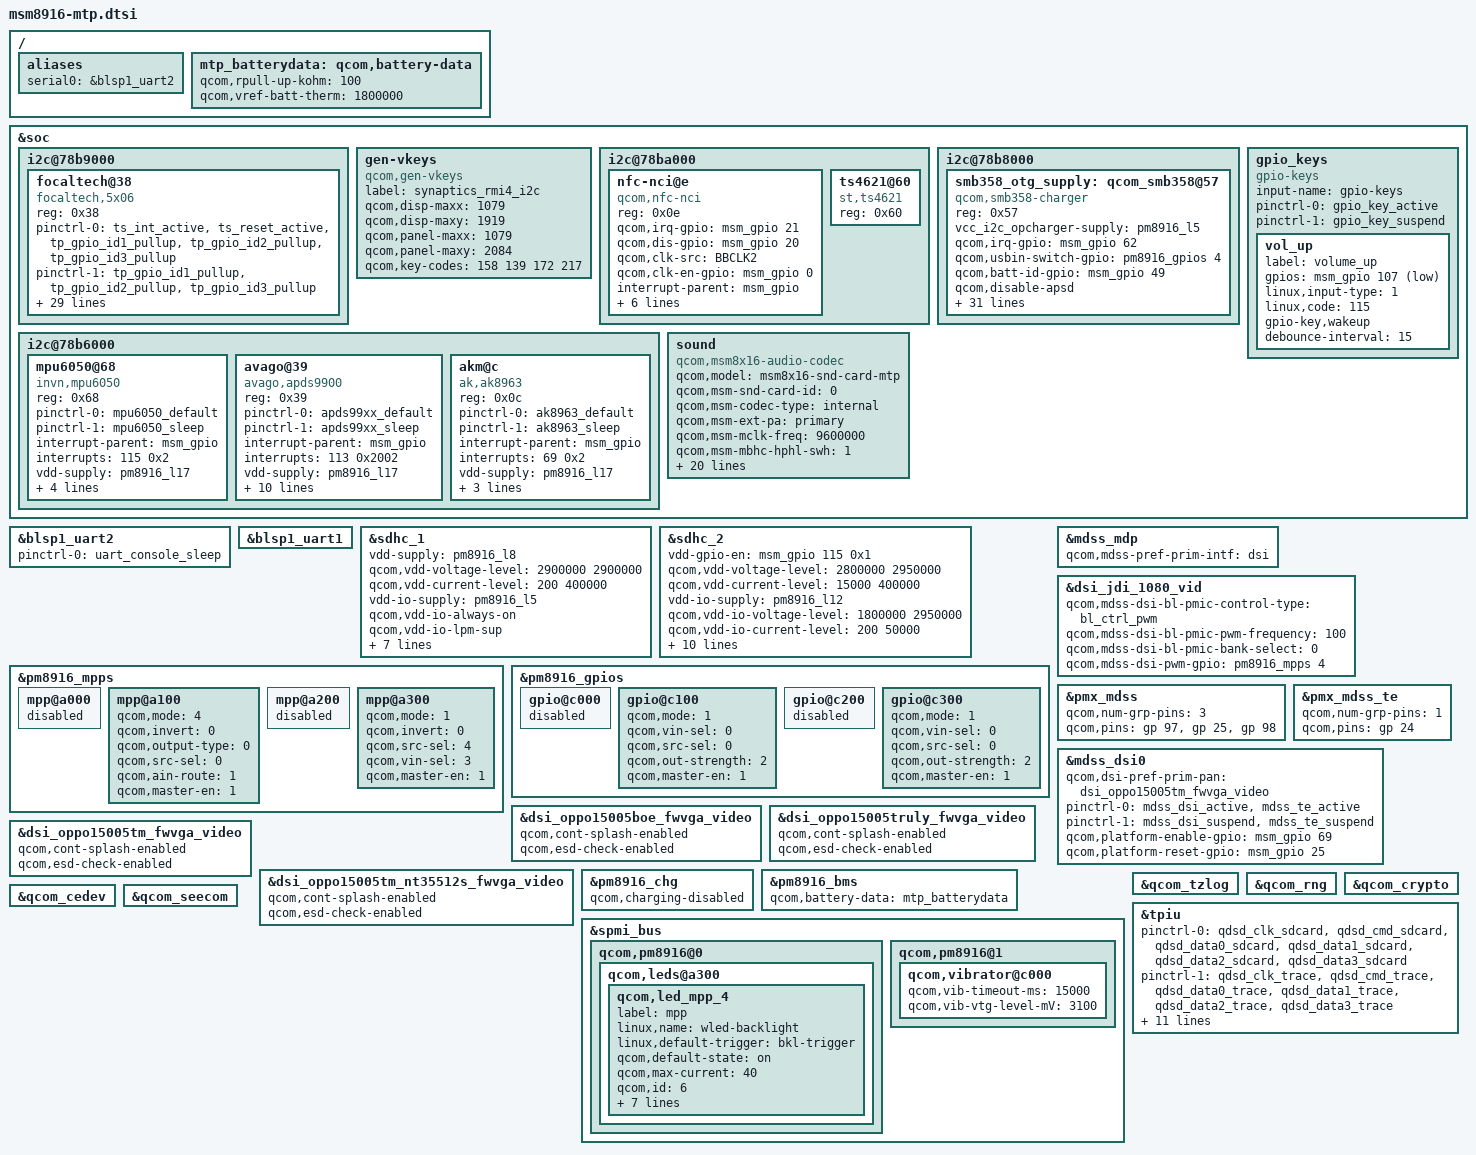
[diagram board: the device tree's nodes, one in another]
/* Copyright (c) 2014, The Linux Foundation. All rights reserved.
 *
 * This program is free software; you can redistribute it and/or modify
 * it under the terms of the GNU General Public License version 2 and
 * only version 2 as published by the Free Software Foundation.
 *
 * This program is distributed in the hope that it will be useful,
 * but WITHOUT ANY WARRANTY; without even the implied warranty of
 * MERCHANTABILITY or FITNESS FOR A PARTICULAR PURPOSE.  See the
 * GNU General Public License for more details.
 */

#include "msm8916.dtsi"
#include "msm8916-pinctrl.dtsi"
#include "msm8916-camera-sensor-mtp.dtsi"
/*YongPeng.Yi@PhoneSW.Multimedia, 2015/01/08 Add for 15005 LCD*/
#include "dsi-panel-oppo15005tm-fwvga-video.dtsi"
#include "dsi-panel-oppo15005boe-fwvga-video.dtsi"
#include "dsi-panel-oppo15005tm-nt35512s-fwvga-video.dtsi"
/*wuyu@EXP.BaseDrv.LCM, 2015/02/09 add for 15065 LCD*/
#include "dsi-panel-oppo15005truly-fwvga-video.dtsi"

#include "msm8916-generic-sensors.dtsi"
/ {
	aliases {
		serial0 = &blsp1_uart2;
	};
};

&soc {
	i2c@78b9000 { /* BLSP1 QUP5 */
		focaltech@38 {
		compatible = "focaltech,5x06";
		reg = <0x38>;
		
		
		pinctrl-names = "default","tp_id_pull_up","tp_id_pull_down";
		pinctrl-0 = <&ts_int_active &ts_reset_active &tp_gpio_id1_pullup &tp_gpio_id2_pullup &tp_gpio_id3_pullup>;
		pinctrl-1 = <&tp_gpio_id1_pullup   &tp_gpio_id2_pullup   &tp_gpio_id3_pullup>;
		pinctrl-2 = <&tp_gpio_id1_pulldown &tp_gpio_id2_pulldown &tp_gpio_id3_pulldown>;
		
		interrupt-parent = <&msm_gpio>;
		interrupts = <13 0x8>;
		vdd-supply = <&pm8916_l17>;
		vcc_i2c-supply = <&pm8916_l6>;
		focaltech,name = "ft5x06";
		focaltech,family-id = <0x54>;
		focaltech,reset-gpio = <&msm_gpio 21 0x00>;
		focaltech,irq-gpio =<&msm_gpio 13 0x00>;
		focaltech,id1-gpio = <&msm_gpio 109 0x00>;
		focaltech,id2-gpio = <&msm_gpio 114 0x00>;
		focaltech,id3-gpio = <&msm_gpio 121 0x00>;
		focaltech,display-coords = <0 0 480 854>;
		focaltech,panel-coords = <0 0 480 854>;
		focaltech,button-map= <85 100 900>;
		focaltech,no-force-update;
		focaltech,i2c-pull-up;
		focaltech,group-id = <1>;
		focaltech,hard-reset-delay-ms = <20>;
		focaltech,soft-reset-delay-ms = <150>;
		focaltech,num-max-touches = <10>;
		focaltech,fw-name = "FT_Upgrade_App.i";
		focaltech,fw-delay-aa-ms = <50>;
		focaltech,fw-delay-55-ms = <30>;
		focaltech,fw-upgrade-id1 = <0x79>;
		focaltech,fw-upgrade-id2 = <0x03>;
		focaltech,fw-delay-readid-ms = <10>;
		focaltech,fw-delay-era-flsh-ms = <2000>;
		};
	};

	gen-vkeys {
		compatible = "qcom,gen-vkeys";
		label = "synaptics_rmi4_i2c";
		qcom,disp-maxx = <1079>;
		qcom,disp-maxy = <1919>;
		qcom,panel-maxx = <1079>;
		qcom,panel-maxy = <2084>;
		qcom,key-codes = <158 139 172 217>;
	};

	i2c@78ba000 { /* BLSP1 QUP6 */
		nfc-nci@e {
			compatible = "qcom,nfc-nci";
			reg = <0x0e>;
			qcom,irq-gpio = <&msm_gpio 21 0x00>;
			qcom,dis-gpio = <&msm_gpio 20 0x00>;
			qcom,clk-src = "BBCLK2";
			qcom,clk-en-gpio = <&msm_gpio 0 0x00>;
			interrupt-parent = <&msm_gpio>;
			interrupts = <21 0>;
			interrupt-names = "nfc_irq";
			pinctrl-names = "nfc_active","nfc_suspend";
			pinctrl-0 = <&nfc_int_active &nfc_disable_active>;
			pinctrl-1 = <&nfc_int_suspend &nfc_disable_suspend>;
			qcom,clk-gpio = <&pm8916_gpios 2 0>;
			clocks = <&clock_rpm clk_bb_clk2_pin>;
			clock-names = "ref_clk";
		};
                /* OPPO 2014-10-24 John.Xu@Audio.Driver Add begin for ts4621 */
                //#ifdef VENDOR_EDIT
    	        ts4621@60 {
    	                  status = "okay";
                          compatible = "st,ts4621";
                          reg = <0x60>;
                };
               //#endif
               /* OPPO 2014-10-24 John.Xu@Audio.Driver Add end */
	};

	i2c@78b6000 { /* BLSP1 QUP2 */
		mpu6050@68 { /* Gyroscope and accelerometer sensor combo */
			compatible = "invn,mpu6050";
			reg = <0x68>;
			pinctrl-names = "mpu_default","mpu_sleep";
			pinctrl-0 = <&mpu6050_default>;
			pinctrl-1 = <&mpu6050_sleep>;
			interrupt-parent = <&msm_gpio>;
			interrupts = <115 0x2>;
			vdd-supply = <&pm8916_l17>;
			vlogic-supply = <&pm8916_l16>;
			vi2c-supply = <&pm8916_l6>;
			invn,gpio-int = <&msm_gpio 115 0x2>;
			invn,place = "Portrait Down Back Side";
		};

		avago@39 { /* Ambient light and proximity sensor */
			compatible = "avago,apds9900";
			reg = <0x39>;
			pinctrl-names = "default","sleep";
			pinctrl-0 = <&apds99xx_default>;
			pinctrl-1 = <&apds99xx_sleep>;
			interrupt-parent = <&msm_gpio>;
			interrupts = <113 0x2002>;
			vdd-supply = <&pm8916_l17>;
			vio-supply = <&pm8916_l6>;
			avago,irq-gpio = <&msm_gpio 113 0x2002>;
			avago,ps-threshold = <600>;
			avago,ps-hysteresis-threshold = <500>;
			avago,ps-pulse = <8>;
			avago,ps-pgain = <0>;
			avago,als-B = <223>;
			avago,als-C = <70>;
			avago,als-D = <142>;
			avago,ga-value = <48>;
		};

		akm@c {
			compatible = "ak,ak8963";
			reg = <0x0c>;
			pinctrl-names = "ak8963_default", "ak8963_sleep";
			pinctrl-0 = <&ak8963_default>;
			pinctrl-1 = <&ak8963_sleep>;
			interrupt-parent = <&msm_gpio>;
			interrupts = <69 0x2>;
			vdd-supply = <&pm8916_l17>;
			vio-supply = <&pm8916_l6>;
			ak,layout = <0x6>;
			ak,auto-report;
		};
	};
	
	/*Fuchun.Liao@Mobile.BSP.CHG 2014-07-31 add to config BSL1 QUP4 for smb358-charger*/
	i2c@78b8000 {	/* BLSP1 QUP4 */
		smb358_otg_supply:	qcom_smb358@57 {
			compatible = "qcom,smb358-charger";
			reg = <0x57>;
			vcc_i2c_opcharger-supply = <&pm8916_l5>;
			qcom,irq-gpio = <&msm_gpio 62 0x00>;
									
			qcom,usbin-switch-gpio = <&pm8916_gpios 4 0>;
			qcom,batt-id-gpio = <&msm_gpio 49 0x00>;
			
			qcom,disable-apsd;
			qcom,using-pmic-therm;
			//qcom,bms-controlled-charging;
			qcom,charger-inhibit-disabled;
			qcom,bms-psy-name = "bms";
			qcom,chg-vadc = <&pm8916_vadc>;
			qcom,chg-adc_tm = <&pm8916_adc_tm>;
			
			qcom,iterm-ma = <100>;								
			qcom,recharge-mv = <200>;							
			qcom,fast-charger-project-sign= <0>;					
			qcom,fastchg-current-max-ma = <900>;					
			qcom,input-current-max-ma = <1000>; 				
			qcom,float-voltage-mv = <4320>; 					

			qcom,hot_bat_decidegc = <550>;						
			qcom,temp_hot_vfloat_mv = <4100>;						
			qcom,temp_hot_fastchg_current_ma = <512>;				

			qcom,warm_bat_decidegc = <450>; 				
			qcom,temp_warm_vfloat_mv = <4320>;				
			qcom,temp_warm_fastchg_current_ma = <900>; 		

			qcom,pre_normal_bat_decidegc = <200>;					
			qcom,temp_pre_normal_vfloat_mv = <4320>;				
			qcom,temp_pre_normal_fastchg_current_ma = <900>;		

			qcom,pre_cool_bat_decidegc = <100>; 				
			qcom,temp_pre_cool_vfloat_mv = <4200>;				
			qcom,temp_pre_cool_fastchg_current_ma = <512>;		

			qcom,cool_bat_decidegc = <0>;							
			qcom,temp_cool_vfloat_mv = <4000>;					
			qcom,temp_cool_fastchg_current_ma = <250>;		

			qcom,cold_bat_decidegc = <100>; 				
			qcom,bat_present_decidegc = <200>;
			qcom,non_standard_vfloat_mv = <4000>;
			qcom,non_standard_fastchg_current_ma = <512>;
			regulator-name = "smb358_otg_vreg";
		};

	};
	/*Fuchun.Liao add end*/
	
	sound {
		compatible = "qcom,msm8x16-audio-codec";
		qcom,model = "msm8x16-snd-card-mtp";
		qcom,msm-snd-card-id = <0>;
		qcom,msm-codec-type = "internal";
		qcom,msm-ext-pa = "primary";
		qcom,msm-mclk-freq = <9600000>;
		/*xiang.fei@Multimedia, 2014/07/29, Modify for headset*/
		/*qcom,msm-mbhc-hphl-swh = <0>;*/
		qcom,msm-mbhc-hphl-swh = <1>;
		/*xiang.fei@Multimedia, 2014/07/29, Modify end*/
		qcom,msm-mbhc-gnd-swh = <0>;
		qcom,msm-micbias1-ext-cap;
		/*John.Xu@Multimedia, 2015/01/09, Modify for headset*/
		/*qcom,msm-hs-micbias-type = "internal";*/
		qcom,msm-hs-micbias-type = "external";
		/*John.Xu@Multimedia, 2015/01/09, Modify end*/
		qcom,audio-routing =
			"RX_BIAS", "MCLK",
			"SPK_RX_BIAS", "MCLK",
			"INT_LDO_H", "MCLK",
			"MIC BIAS External", "Handset Mic",
			"MIC BIAS Internal2", "Headset Mic",
			"MIC BIAS External", "Secondary Mic",
			"AMIC1", "MIC BIAS External",
			"AMIC2", "MIC BIAS Internal2",
			"AMIC3", "MIC BIAS External";
		pinctrl-names = "cdc_lines_act",
				"cdc_lines_sus",
				"cdc_lines_sec_ext_act",
				"cdc_lines_sec_ext_sus",
				"cross_conn_det_act",
				"cross_conn_det_sus";
		pinctrl-0 = <&cdc_pdm_lines_act>;
		pinctrl-1 = <&cdc_pdm_lines_sus>;
		pinctrl-2 = <&cdc_pdm_lines_act &cdc_ext_pa_act
						&cdc_ext_pa_ws_act>;
		pinctrl-3 = <&cdc_pdm_lines_sus &cdc_ext_pa_sus
						&cdc_ext_pa_ws_sus>;
		pinctrl-4 = <&cross_conn_det_act>;
		pinctrl-5 = <&cross_conn_det_sus>;
		/*xiang.fei@Multimedia, 2014/09/10, Add end*/
		/*qcom,cdc-us-euro-gpios = <&msm_gpio 120 0>;*/
		/*xiang.fei@Multimedia, 2014/07/29, Add for yda145*/
		spk-pa-en = <&msm_gpio 120 0x00>;
		/*xiang.fei@Multimedia, 2014/09/10, Add end*/
		/* OPPO 2015-01-09 John.Xu@Audio.Driver Add begin for boost for yda145 */
                //#ifdef VENDOR_EDIT
                yda145_boost-en = <&msm_gpio 17 0x00>;
               //#endif
               /* OPPO 2015-01-09 John.Xu@Audio.Driver Add end */
	};
};

&blsp1_uart2 {
	status = "ok";
	pinctrl-names = "default";
	pinctrl-0 = <&uart_console_sleep>;
};

&soc {
	gpio_keys {
		compatible = "gpio-keys";
		input-name = "gpio-keys";
		pinctrl-names = "tlmm_gpio_key_active","tlmm_gpio_key_suspend";
		pinctrl-0 = <&gpio_key_active>;
		pinctrl-1 = <&gpio_key_suspend>;
/*#ifdef VENDOR_EDIT ye.zhang@BSP, delete because they are not used*/
/*
		camera_focus {
			label = "camera_focus";
			gpios = <&msm_gpio 108 0x1>;
			linux,input-type = <1>;
			linux,code = <0x210>;
			gpio-key,wakeup;
			debounce-interval = <15>;
		};

		camera_snapshot {
			label = "camera_snapshot";
			gpios = <&msm_gpio 109 0x1>;
			linux,input-type = <1>;
			linux,code = <0x2fe>;
			gpio-key,wakeup;
			debounce-interval = <15>;
		};
*/
/*#endif//VENDOR_EDIT*/
		vol_up {
			label = "volume_up";
			gpios = <&msm_gpio 107 0x1>;
			linux,input-type = <1>;
			linux,code = <115>;
			gpio-key,wakeup;
			debounce-interval = <15>;
		};
	};
};

&blsp1_uart1 {
	status = "ok";
};

&sdhc_1 {
	vdd-supply = <&pm8916_l8>;
	qcom,vdd-voltage-level = <2900000 2900000>;
	qcom,vdd-current-level = <200 400000>;

	vdd-io-supply = <&pm8916_l5>;
	qcom,vdd-io-always-on;
	qcom,vdd-io-lpm-sup;
	qcom,vdd-io-voltage-level = <1800000 1800000>;
	qcom,vdd-io-current-level = <200 60000>;

	pinctrl-names = "active", "sleep";
	pinctrl-0 = <&sdc1_clk_on &sdc1_cmd_on &sdc1_data_on>;
	pinctrl-1 = <&sdc1_clk_off &sdc1_cmd_off &sdc1_data_off>;

	qcom,nonremovable;

	status = "ok";
};

&sdhc_2 {

//#ifndef VENDOR_EDIT //caven.han@BSP.Driver, 2014-09-13, Modify for tf card vdd supply change,2014-11-04
//	vdd-supply = <&pm8916_l11>;
//#else
	vdd-gpio-en = <&msm_gpio 115 0x1>;
//#endif/*VENDOR_EDIT*/

 	qcom,vdd-voltage-level = <2800000 2950000>;
 	qcom,vdd-current-level = <15000 400000>;

	vdd-io-supply = <&pm8916_l12>;
	qcom,vdd-io-voltage-level = <1800000 2950000>;
	qcom,vdd-io-current-level = <200 50000>;

	pinctrl-names = "active", "sleep";
	pinctrl-0 = <&sdc2_clk_on &sdc2_cmd_on &sdc2_data_on &sdc2_cd_on>;
	pinctrl-1 = <&sdc2_clk_off &sdc2_cmd_off &sdc2_data_off &sdc2_cd_off>;

	#address-cells = <0>;
	interrupt-parent = <&sdhc_2>;
	interrupts = <0 1 2>;
	#interrupt-cells = <1>;
	interrupt-map-mask = <0xffffffff>;
	interrupt-map = <0 &intc 0 125 0
			1 &intc 0 221 0
			2 &msm_gpio 38 0>;
	interrupt-names = "hc_irq", "pwr_irq", "status_irq";
	//#ifdef VENDOR_EDIT //yixue.ge modify for 14045 tcard hotplug
	//cd-gpios = <&msm_gpio 38 0x1>;
	//#else
	cd-gpios = <&msm_gpio 38 0x0>;
	//#endif

	status = "ok";
};

&pm8916_mpps {
	mpp@a000 { /* MPP 1 */
		/* VDD_PX */
		status = "disabled";
	};

	mpp@a100 { /* MPP 2 */
		/*Fuchun.Liao@Mobile.BSP.CHG 2014-08-08 modify for set MPP2 to iadc_usbin*/
		status = "ok";
		qcom,mode = <4>;		/* QPNP_PIN_MODE_AIN */
		qcom,invert = <0>;		/* Disable invert */
		qcom,output-type = <0>;	/* CMOS */
		qcom,src-sel = <0>;		/* MPP Constant */
		qcom,ain-route = <1>;	/* QPNP_PIN_AIN_AMUX_CH6 = 1 for MPP2*/
		qcom,master-en = <1>;		/* Enable MPP */
		/* Fuchun.Liao modify end */
	};

	mpp@a200 { /* MPP 3 */
		/* VREF DAC */
		status = "disabled";
	};

	mpp@a300 { /* MPP 4 */
		/* Backlight PWM */
		qcom,mode = <1>;		/* Digital output */
		qcom,invert = <0>;		/* Disable invert */
		qcom,src-sel = <4>;		/* DTEST1 */
		qcom,vin-sel = <3>;		/* 1.8V */
		qcom,master-en = <1>;		/* Enable MPP */
	};
};

&pm8916_gpios {
	gpio@c000 { /* GPIO 1 */
		/* Battery UICC Alarm */
		status = "disabled";
	};

	gpio@c100 { /* GPIO 2 */
		/*Fuchun.Liao@Mobile.BSP.CHG 2014-08-06 set pm_gpio2 output 1.8v*/
		status = "ok";
		qcom,mode = <1>; /* QPNP_PIN_MODE_DIG_OUT */
		qcom,vin-sel = <0>; /* VPH_PWR */
		qcom,src-sel = <0>; /* QPNP_PIN_SEL_FUNC_CONSTANT */
		qcom,out-strength = <2>; /* QPNP_PIN_OUT_STRENGTH_MED */
		qcom,master-en = <1>;
		/*Fuchun.Liao modify end*/
	};

	gpio@c200 { /* GPIO 3 */
		/* External regulator control for WTR */
		status = "disabled";
	};

	gpio@c300 { /* GPIO 4 */
		/* External regulator control for APC */
		/*Fuchun.Liao@Mobile.BSP.CHG 2014-08-06 modify pm_gpio_4 output VPH_PWR for DVT PCBA*/
		status = "ok";
		qcom,mode = <1>; /* QPNP_PIN_MODE_DIG_OUT */
		qcom,vin-sel = <0>; /* VPH_PWR */
		qcom,src-sel = <0>; /* QPNP_PIN_SEL_FUNC_CONSTANT */
		qcom,out-strength = <2>; /* QPNP_PIN_OUT_STRENGTH_MED */
		qcom,master-en = <1>;
		/*Fuchun.Liao modify end*/
	};
};

#include "dsi-panel-jdi-1080p-video.dtsi"

&mdss_mdp {
	qcom,mdss-pref-prim-intf = "dsi";
};

&dsi_jdi_1080_vid {
	qcom,mdss-dsi-bl-pmic-control-type = "bl_ctrl_pwm";
	qcom,mdss-dsi-bl-pmic-pwm-frequency = <100>;
	qcom,mdss-dsi-bl-pmic-bank-select = <0>;
	qcom,mdss-dsi-pwm-gpio = <&pm8916_mpps 4 0>;

};

&pmx_mdss {
	qcom,num-grp-pins = <3>;
	qcom,pins = <&gp 97>, <&gp 25>, <&gp 98>;
};

&pmx_mdss_te {
	qcom,num-grp-pins = <1>;
	qcom,pins = <&gp 24>;
};

&mdss_dsi0 {
/*YongPeng.Yi@PhoneSW.Multimedia, 2015/01/06 Add for 15005 LCD*/
	qcom,dsi-pref-prim-pan = <&dsi_oppo15005tm_fwvga_video>;
	pinctrl-names = "mdss_default", "mdss_sleep";
	pinctrl-0 = <&mdss_dsi_active &mdss_te_active>;
	pinctrl-1 = <&mdss_dsi_suspend &mdss_te_suspend>;

/* YongPeng.Yi@SWDP.MultiMedia, 2015/04/20  Add for 15005 2.8v ldo gpio 69 */
	qcom,platform-enable-gpio = <&msm_gpio 69 0>;
	qcom,platform-reset-gpio = <&msm_gpio 25 0>;
	/*qcom,platform-bklight-en-gpio = <&msm_gpio 98 0>;*/
};

&dsi_oppo15005boe_fwvga_video{
	qcom,cont-splash-enabled;
	qcom,esd-check-enabled;
};

&dsi_oppo15005truly_fwvga_video{
	qcom,cont-splash-enabled;
	qcom,esd-check-enabled;
};

&dsi_oppo15005tm_fwvga_video{
	qcom,cont-splash-enabled;
	qcom,esd-check-enabled;
};

&dsi_oppo15005tm_nt35512s_fwvga_video{
	qcom,cont-splash-enabled;
	qcom,esd-check-enabled;
};


&pm8916_chg {
	status = "ok";
	qcom,charging-disabled;
};

/ {
	mtp_batterydata: qcom,battery-data {
		qcom,rpull-up-kohm = <100>;
		qcom,vref-batt-therm = <1800000>;

		//#include "batterydata-palladium.dtsi"
		#include "batterydata-oppo-15005-2000mah.dtsi"
	};
};

&pm8916_bms {
	status = "ok";
	qcom,battery-data = <&mtp_batterydata>;
};

&spmi_bus {
	qcom,pm8916@0 {
/*	Fuchun.Liao@Mobile.BSP.CHG 2014-08-13 del for MPP2 used to read smb358 current */
/*
		qcom,leds@a100 {
			status = "okay";
			qcom,led_mpp_2 {
				label = "mpp";
				linux,name = "button-backlight";
				linux,default-trigger = "none";
				qcom,default-state = "off";
				qcom,max-current = <40>;
				qcom,current-setting = <5>;
				qcom,id = <6>;
				qcom,mode = "manual";
				qcom,source-sel = <1>;
				qcom,mode-ctrl = <0x60>;
			};
		};
*/
/* Fuchun.Liao del end */
		/*YongPeng.Yi@PhoneSW.Multimedia, 2015/01/07 Add for 15005 LCD Backlight Driver*/
		qcom,leds@a300 {
			status = "okay";
			qcom,led_mpp_4 {
				label = "mpp";
				linux,name = "wled-backlight";
				linux,default-trigger = "bkl-trigger";
				qcom,default-state = "on";
				qcom,max-current = <40>;
				qcom,id = <6>;
				qcom,source-sel = <8>;
				qcom,mode-ctrl = <0x10>;
				qcom,pwm-channel = <0>;
				qcom,pwm-us = <31>;
				qcom,vin-ctrl = <0x03>;
				qcom,mode = "pwm";
				qcom,min-brightness = <19>;
			};
		};
	};
};

&qcom_tzlog {
	status = "okay";
};

&qcom_rng {
	status = "okay";
};

&qcom_crypto {
	status = "okay";
};

&qcom_cedev {
	status = "okay";
};

&qcom_seecom {
	status = "okay";
};

/* CoreSight */
&tpiu {
      pinctrl-names = "sdcard", "trace", "swduart",
		      "swdtrc", "jtag", "spmi";
       /* NIDnT */
      pinctrl-0 = <&qdsd_clk_sdcard &qdsd_cmd_sdcard
                  &qdsd_data0_sdcard &qdsd_data1_sdcard
                  &qdsd_data2_sdcard &qdsd_data3_sdcard>;
      pinctrl-1 = <&qdsd_clk_trace &qdsd_cmd_trace
                  &qdsd_data0_trace &qdsd_data1_trace
                  &qdsd_data2_trace &qdsd_data3_trace>;
      pinctrl-2 = <&qdsd_cmd_swduart &qdsd_data0_swduart
                  &qdsd_data1_swduart &qdsd_data2_swduart
                  &qdsd_data3_swduart>;
      pinctrl-3 = <&qdsd_clk_swdtrc &qdsd_cmd_swdtrc
                  &qdsd_data0_swdtrc &qdsd_data1_swdtrc
                  &qdsd_data2_swdtrc &qdsd_data3_swdtrc>;
      pinctrl-4 = <&qdsd_cmd_jtag &qdsd_data0_jtag
                  &qdsd_data1_jtag &qdsd_data2_jtag
                  &qdsd_data3_jtag>;
      pinctrl-5 = <&qdsd_clk_spmi &qdsd_cmd_spmi
                  &qdsd_data0_spmi &qdsd_data3_spmi>;
};

&spmi_bus {
	qcom,pm8916@1 {
		qcom,vibrator@c000 {
			status = "okay";
			qcom,vib-timeout-ms = <15000>;
			qcom,vib-vtg-level-mV = <3100>;
		};
	};
};
